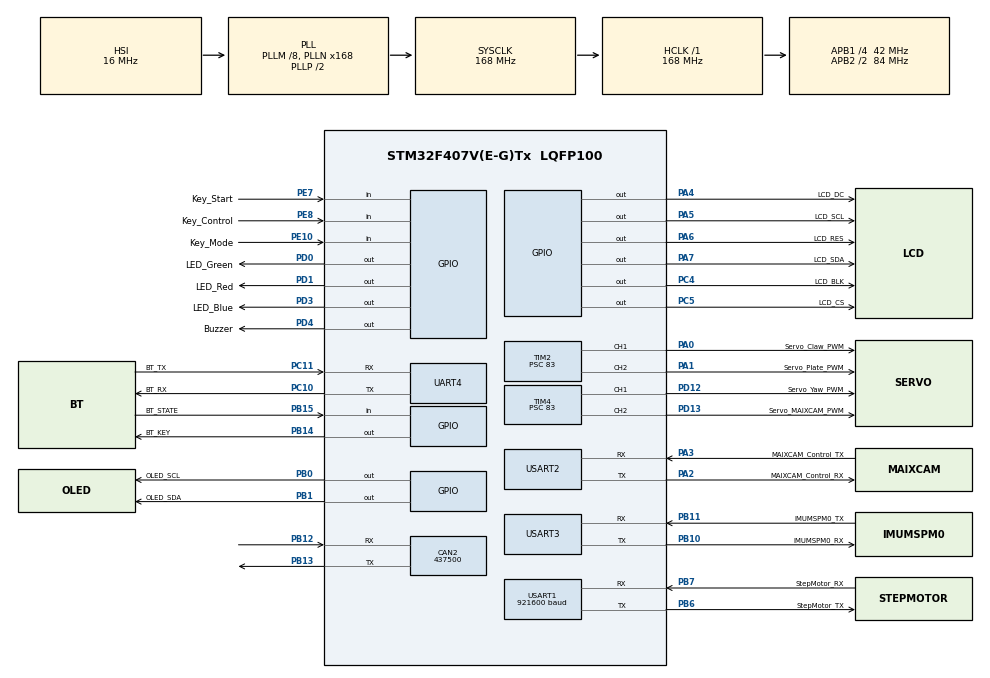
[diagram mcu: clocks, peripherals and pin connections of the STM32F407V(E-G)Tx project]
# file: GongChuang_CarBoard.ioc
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CAN2.BS1=CAN_BS1_2TQ
CAN2.BS2=CAN_BS2_3TQ
CAN2.CalculateBaudRate=437500
CAN2.CalculateTimeBit=2285
CAN2.CalculateTimeQuantum=380.95238095238096
Dma.Request0=UART4_RX
Dma.Request1=USART2_RX
Dma.Request2=USART1_RX
Dma.Request3=USART1_TX
Dma.UART4_RX.0.Direction=DMA_PERIPH_TO_MEMORY
Dma.UART4_RX.0.FIFOMode=DMA_FIFOMODE_DISABLE
Dma.UART4_RX.0.Instance=DMA1_Stream2
Dma.UART4_RX.0.MemDataAlignment=DMA_MDATAALIGN_BYTE
Dma.UART4_RX.0.MemInc=DMA_MINC_ENABLE
Dma.UART4_RX.0.Mode=DMA_NORMAL
Dma.UART4_RX.0.PeriphDataAlignment=DMA_PDATAALIGN_BYTE
Dma.UART4_RX.0.PeriphInc=DMA_PINC_DISABLE
Dma.UART4_RX.0.Priority=DMA_PRIORITY_LOW
Dma.USART1_RX.2.Direction=DMA_PERIPH_TO_MEMORY
Dma.USART1_RX.2.FIFOMode=DMA_FIFOMODE_DISABLE
Dma.USART1_RX.2.Instance=DMA2_Stream2
Dma.USART1_RX.2.MemDataAlignment=DMA_MDATAALIGN_BYTE
Dma.USART1_RX.2.MemInc=DMA_MINC_ENABLE
Dma.USART1_RX.2.Mode=DMA_NORMAL
Dma.USART1_RX.2.PeriphDataAlignment=DMA_PDATAALIGN_BYTE
Dma.USART1_RX.2.PeriphInc=DMA_PINC_DISABLE
Dma.USART1_RX.2.Priority=DMA_PRIORITY_HIGH
Dma.USART1_TX.3.Direction=DMA_MEMORY_TO_PERIPH
Dma.USART1_TX.3.FIFOMode=DMA_FIFOMODE_DISABLE
Dma.USART1_TX.3.Instance=DMA2_Stream7
Dma.USART1_TX.3.MemDataAlignment=DMA_MDATAALIGN_BYTE
Dma.USART1_TX.3.MemInc=DMA_MINC_ENABLE
Dma.USART1_TX.3.Mode=DMA_NORMAL
Dma.USART1_TX.3.PeriphDataAlignment=DMA_PDATAALIGN_BYTE
Dma.USART1_TX.3.PeriphInc=DMA_PINC_DISABLE
Dma.USART1_TX.3.Priority=DMA_PRIORITY_VERY_HIGH
Dma.USART2_RX.1.Direction=DMA_PERIPH_TO_MEMORY
Dma.USART2_RX.1.FIFOMode=DMA_FIFOMODE_DISABLE
Dma.USART2_RX.1.Instance=DMA1_Stream5
Dma.USART2_RX.1.MemDataAlignment=DMA_MDATAALIGN_BYTE
Dma.USART2_RX.1.MemInc=DMA_MINC_ENABLE
Dma.USART2_RX.1.Mode=DMA_NORMAL
Dma.USART2_RX.1.PeriphDataAlignment=DMA_PDATAALIGN_BYTE
Dma.USART2_RX.1.PeriphInc=DMA_PINC_DISABLE
Dma.USART2_RX.1.Priority=DMA_PRIORITY_HIGH
Mcu.Family=STM32F4
Mcu.Name=STM32F407V(E-G)Tx
Mcu.Package=LQFP100
NVIC.DMA1_Stream2_IRQn=true\:0\:0\:false\:false\:true\:false\:true\:true
NVIC.DMA1_Stream5_IRQn=true\:0\:0\:false\:false\:true\:false\:true\:true
NVIC.DMA2_Stream2_IRQn=true\:0\:0\:false\:false\:true\:false\:true\:true
NVIC.DMA2_Stream7_IRQn=true\:0\:0\:false\:false\:true\:false\:true\:true
NVIC.PriorityGroup=NVIC_PRIORITYGROUP_4
NVIC.TIM1_UP_TIM10_IRQn=true\:1\:0\:true\:false\:true\:true\:true\:true
NVIC.UART4_IRQn=true\:5\:0\:true\:false\:true\:true\:true\:true
NVIC.USART1_IRQn=true\:1\:0\:true\:false\:true\:true\:true\:true
NVIC.USART2_IRQn=true\:2\:0\:true\:false\:true\:true\:true\:true
NVIC.USART3_IRQn=true\:0\:0\:true\:false\:true\:true\:true\:true
PA0-WKUP.GPIO_Label=Servo_Claw_PWM
PA0-WKUP.Signal=S_TIM2_CH1_ETR
PA1.GPIO_Label=Servo_Plate_PWM
PA1.Signal=S_TIM2_CH2
PA13.Mode=Serial_Wire
PA13.Signal=SYS_JTMS-SWDIO
PA14.Mode=Serial_Wire
PA14.Signal=SYS_JTCK-SWCLK
PA2.GPIO_Label=MAIXCAM_Control_RX
PA2.Mode=Asynchronous
PA2.Signal=USART2_TX
PA3.GPIO_Label=MAIXCAM_Control_TX
PA3.Mode=Asynchronous
PA3.Signal=USART2_RX
PA4.GPIO_Label=LCD_DC
PA4.PinState=GPIO_PIN_SET
PA4.Signal=GPIO_Output
PA4.Stacked=true
PA5.GPIO_Label=LCD_SCL
PA5.GPIO_ModeDefaultOutputPP=GPIO_MODE_OUTPUT_PP
PA5.GPIO_Speed=GPIO_SPEED_FREQ_VERY_HIGH
PA5.PinState=GPIO_PIN_SET
PA5.Signal=GPIO_Output
PA6.GPIO_Label=LCD_RES
PA6.PinState=GPIO_PIN_SET
PA6.Signal=GPIO_Output
PA6.Stacked=true
PA7.GPIO_Label=LCD_SDA
PA7.GPIO_ModeDefaultOutputPP=GPIO_MODE_OUTPUT_PP
PA7.GPIO_Speed=GPIO_SPEED_FREQ_VERY_HIGH
PA7.PinState=GPIO_PIN_SET
PA7.Signal=GPIO_Output
PB0.GPIO_Label=OLED_SCL
PB0.GPIO_ModeDefaultOutputPP=GPIO_MODE_OUTPUT_OD
PB0.GPIO_PuPd=GPIO_PULLUP
PB0.GPIO_Speed=GPIO_SPEED_FREQ_MEDIUM
PB0.PinState=GPIO_PIN_SET
PB0.Signal=GPIO_Output
PB1.GPIO_Label=OLED_SDA
PB1.GPIO_ModeDefaultOutputPP=GPIO_MODE_OUTPUT_OD
PB1.GPIO_PuPd=GPIO_PULLUP
PB1.GPIO_Speed=GPIO_SPEED_FREQ_MEDIUM
PB1.PinState=GPIO_PIN_SET
PB1.Signal=GPIO_Output
PB10.GPIO_Label=IMUMSPM0_RX
PB10.Mode=Asynchronous
PB10.Signal=USART3_TX
PB11.GPIO_Label=IMUMSPM0_TX
PB11.Mode=Asynchronous
PB11.Signal=USART3_RX
PB12.Mode=CAN_Activate
PB12.Signal=CAN2_RX
PB13.Mode=CAN_Activate
PB13.Signal=CAN2_TX
PB14.GPIO_Label=BT_KEY
PB14.Signal=GPIO_Output
PB15.GPIO_Label=BT_STATE
PB15.GPIO_PuPd=GPIO_PULLUP
PB15.Signal=GPIO_Input
PB6.GPIO_Label=StepMotor_TX
PB6.Mode=Asynchronous
PB6.Signal=USART1_TX
PB7.GPIO_Label=StepMotor_RX
PB7.Mode=Asynchronous
PB7.Signal=USART1_RX
PC10.GPIO_Label=BT_RX
PC10.Mode=Asynchronous
PC10.Signal=UART4_TX
PC11.GPIO_Label=BT_TX
PC11.Mode=Asynchronous
PC11.Signal=UART4_RX
PC14-OSC32_IN.Mode=LSE-External-Oscillator
PC14-OSC32_IN.Signal=RCC_OSC32_IN
PC15-OSC32_OUT.Mode=LSE-External-Oscillator
PC15-OSC32_OUT.Signal=RCC_OSC32_OUT
PC4.GPIO_Label=LCD_BLK
PC4.PinState=GPIO_PIN_SET
PC4.Signal=GPIO_Output
PC5.GPIO_Label=LCD_CS
PC5.GPIO_PuPd=GPIO_NOPULL
PC5.GPIO_Speed=GPIO_SPEED_FREQ_MEDIUM
PC5.PinState=GPIO_PIN_SET
PC5.Signal=GPIO_Output
PD0.GPIO_Label=LED_Green
PD0.Signal=GPIO_Output
PD1.GPIO_Label=LED_Red
PD1.Signal=GPIO_Output
PD12.GPIO_Label=Servo_Yaw_PWM
PD12.Signal=S_TIM4_CH1
PD13.GPIO_Label=Servo_MAIXCAM_PWM
PD13.Signal=S_TIM4_CH2
PD3.GPIO_Label=LED_Blue
PD3.Signal=GPIO_Output
PD4.GPIO_Label=Buzzer
PD4.PinState=GPIO_PIN_RESET
PD4.Signal=GPIO_Output
PE10.GPIO_Label=Key_Mode
PE10.GPIO_PuPd=GPIO_PULLUP
PE10.Signal=GPIO_Input
PE7.GPIO_Label=Key_Start
PE7.GPIO_PuPd=GPIO_PULLUP
PE7.Signal=GPIO_Input
PE8.GPIO_Label=Key_Control
PE8.GPIO_PuPd=GPIO_PULLUP
PE8.Signal=GPIO_Input
PH0-OSC_IN.Mode=HSE-External-Oscillator
PH0-OSC_IN.Signal=RCC_OSC_IN
PH1-OSC_OUT.Mode=HSE-External-Oscillator
PH1-OSC_OUT.Signal=RCC_OSC_OUT
ProjectManager.HeapSize=0x200
ProjectManager.StackSize=0x2000
ProjectManager.TargetToolchain=MDK-ARM V5.32
RCC.48MHZClocksFreq_Value=84000000
RCC.AHBFreq_Value=168000000
RCC.APB1CLKDivider=RCC_HCLK_DIV4
RCC.APB1Freq_Value=42000000
RCC.APB1TimFreq_Value=84000000
RCC.APB2CLKDivider=RCC_HCLK_DIV2
RCC.APB2Freq_Value=84000000
RCC.APB2TimFreq_Value=168000000
RCC.CortexFreq_Value=168000000
RCC.HCLKFreq_Value=168000000
RCC.HSE_VALUE=25000000
RCC.HSI_VALUE=16000000
RCC.PLLM=8
RCC.PLLN=168
RCC.SYSCLKFreq_VALUE=168000000
RCC.SYSCLKSource=RCC_SYSCLKSOURCE_PLLCLK
RCC.VCOOutputFreq_Value=336000000
SH.S_TIM2_CH1_ETR.0=TIM2_CH1,PWM Generation1 CH1
SH.S_TIM2_CH2.0=TIM2_CH2,PWM Generation2 CH2
SH.S_TIM4_CH1.0=TIM4_CH1,PWM Generation1 CH1
SH.S_TIM4_CH2.0=TIM4_CH2,PWM Generation2 CH2
TIM1.Period=999
TIM1.Prescaler=167
TIM2.Channel-PWM\ Generation1\ CH1=TIM_CHANNEL_1
TIM2.Channel-PWM\ Generation2\ CH2=TIM_CHANNEL_2
TIM2.Period=19999
TIM2.Prescaler=83
TIM4.Channel-PWM\ Generation1\ CH1=TIM_CHANNEL_1
TIM4.Channel-PWM\ Generation2\ CH2=TIM_CHANNEL_2
TIM4.Period=19999
TIM4.Prescaler=83
UART4.VirtualMode=Asynchronous
USART1.BaudRate=921600
USART1.VirtualMode=VM_ASYNC
USART2.VirtualMode=VM_ASYNC
USART3.VirtualMode=VM_ASYNC
VP_TIM1_VS_ClockSourceINT.Mode=Internal
VP_TIM2_VS_ClockSourceINT.Mode=Internal
VP_TIM4_VS_ClockSourceINT.Mode=Internal
board=custom

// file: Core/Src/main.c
/* USER CODE BEGIN Header */
/**
  ******************************************************************************
  * @file           : main.c
  * @brief          : Main program body
  ******************************************************************************
  * @attention
  *
  * Copyright (c) 2026 STMicroelectronics.
  * All rights reserved.
  *
  * This software is licensed under terms that can be found in the LICENSE file
  * in the root directory of this software component.
  * If no LICENSE file comes with this software, it is provided AS-IS.
  *
  ******************************************************************************
  */
/* USER CODE END Header */
#include "main.h"
#include "can.h"
#include "dma.h"
#include "tim.h"
#include "usart.h"
#include "gpio.h"

/* USER CODE BEGIN Includes */
#include "App.h"
/* USER CODE END Includes */

void SystemClock_Config(void);

int main(void)
{

  /* MCU Configuration--------------------------------------------------------*/

  /* Reset of all peripherals, Initializes the Flash interface and the Systick. */
  HAL_Init();

  /* Configure the system clock */
  SystemClock_Config();

  /* Initialize all configured peripherals */
  MX_GPIO_Init();
  MX_DMA_Init();
  MX_TIM1_Init();
  MX_TIM2_Init();
  MX_UART4_Init();
  MX_USART3_UART_Init();
  MX_USART2_UART_Init();
  MX_CAN2_Init();
  MX_USART1_UART_Init();
  MX_TIM4_Init();
  /* USER CODE BEGIN 2 */

  HAL_Delay(5000);
  App_Init();

  /* USER CODE END 2 */

  /* Infinite loop */
  /* USER CODE BEGIN WHILE */
  while (1)
  {
      App_Loop();

    /* USER CODE END WHILE */

  }
}

void SystemClock_Config(void)
{
  RCC_OscInitTypeDef RCC_OscInitStruct = {0};
  RCC_ClkInitTypeDef RCC_ClkInitStruct = {0};

  /** Configure the main internal regulator output voltage
  */
  __HAL_RCC_PWR_CLK_ENABLE();
  __HAL_PWR_VOLTAGESCALING_CONFIG(PWR_REGULATOR_VOLTAGE_SCALE1);

  /** Initializes the RCC Oscillators according to the specified parameters
  * in the RCC_OscInitTypeDef structure.
  */
  RCC_OscInitStruct.OscillatorType = RCC_OSCILLATORTYPE_HSI;
  RCC_OscInitStruct.HSIState = RCC_HSI_ON;
  RCC_OscInitStruct.HSICalibrationValue = RCC_HSICALIBRATION_DEFAULT;
  RCC_OscInitStruct.PLL.PLLState = RCC_PLL_ON;
  RCC_OscInitStruct.PLL.PLLSource = RCC_PLLSOURCE_HSI;
  RCC_OscInitStruct.PLL.PLLM = 8;
  RCC_OscInitStruct.PLL.PLLN = 168;
  RCC_OscInitStruct.PLL.PLLP = RCC_PLLP_DIV2;
  RCC_OscInitStruct.PLL.PLLQ = 4;
  if (HAL_RCC_OscConfig(&RCC_OscInitStruct) != HAL_OK)
  {
    Error_Handler();
  }

  /** Initializes the CPU, AHB and APB buses clocks
  */
  RCC_ClkInitStruct.ClockType = RCC_CLOCKTYPE_HCLK|RCC_CLOCKTYPE_SYSCLK
                              |RCC_CLOCKTYPE_PCLK1|RCC_CLOCKTYPE_PCLK2;
  RCC_ClkInitStruct.SYSCLKSource = RCC_SYSCLKSOURCE_PLLCLK;
  RCC_ClkInitStruct.AHBCLKDivider = RCC_SYSCLK_DIV1;
  RCC_ClkInitStruct.APB1CLKDivider = RCC_HCLK_DIV4;
  RCC_ClkInitStruct.APB2CLKDivider = RCC_HCLK_DIV2;

  if (HAL_RCC_ClockConfig(&RCC_ClkInitStruct, FLASH_LATENCY_5) != HAL_OK)
  {
    Error_Handler();
  }
}

void Error_Handler(void)
{
  __disable_irq();
  while (1)
  {
  }
}
